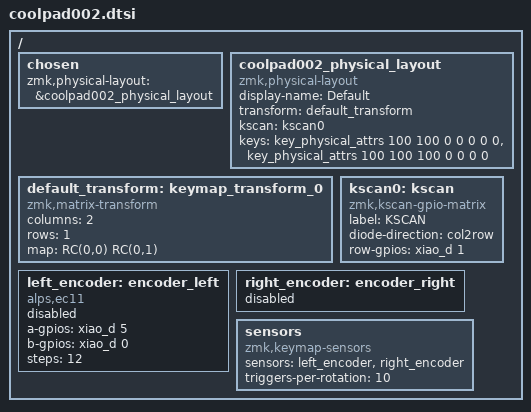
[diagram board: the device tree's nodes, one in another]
#include <dt-bindings/zmk/matrix_transform.h>
#include <physical_layouts.dtsi>

/ {
    chosen {
        zmk,physical-layout = &coolpad002_physical_layout;
    };
    
    coolpad002_physical_layout: coolpad002_physical_layout {
        compatible = "zmk,physical-layout";
        display-name = "Default";
        transform = <&default_transform>;
        kscan = <&kscan0>;

     keys  //                     w   h    x    y     rot    rx    ry
            = <&key_physical_attrs 100 100    0    0       0     0     0>
            , <&key_physical_attrs 100 100  100    0       0     0     0>
            ;
    };

    default_transform: keymap_transform_0 {
        compatible = "zmk,matrix-transform";
        columns = <2>;
        rows = <1>;               
        map = <
           RC(0,0) RC(0,1)       
        >;
    };

    kscan0: kscan {
        compatible = "zmk,kscan-gpio-matrix";
        label = "KSCAN";
        diode-direction = "col2row";
            row-gpios
                = <&xiao_d 1 (GPIO_ACTIVE_HIGH | GPIO_PULL_DOWN)> 
               	
                ;
    };

    left_encoder: encoder_left {
        compatible = "alps,ec11";
        a-gpios = <&xiao_d 5 (GPIO_ACTIVE_HIGH | GPIO_PULL_UP)>;
        b-gpios = <&xiao_d 0 (GPIO_ACTIVE_HIGH | GPIO_PULL_UP)>;
        steps = <12>;
        status = "disabled";
    };

    right_encoder: encoder_right {
        status = "disabled";
    };

    sensors: sensors {
        compatible = "zmk,keymap-sensors";
        sensors = <&left_encoder &right_encoder>;
        triggers-per-rotation = <10>;
    };
};
